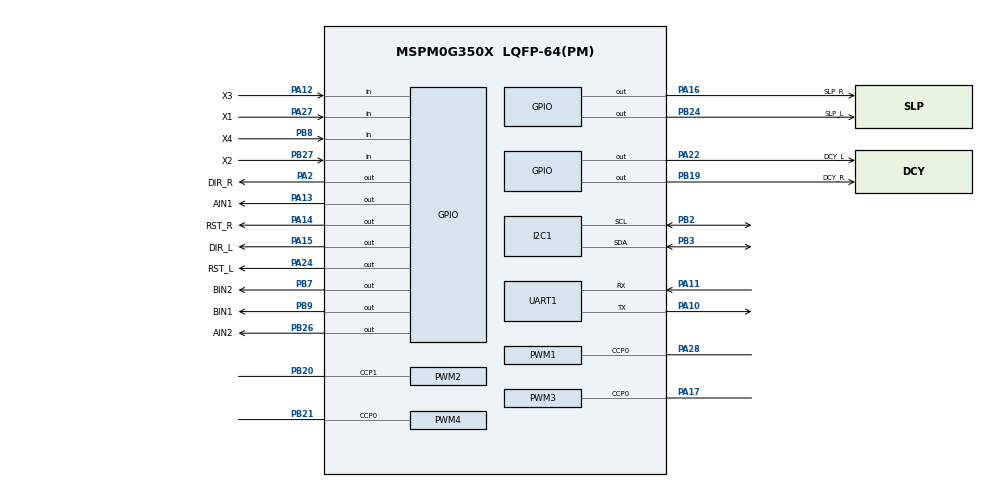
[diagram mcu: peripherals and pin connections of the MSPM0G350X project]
/**
 * @cliArgs --device "MSPM0G350X" --part "Default" --package "LQFP-64(PM)" --product "mspm0_sdk@2.10.00.04"
 * @versions {"tool":"1.26.2+4477"}
 */

/**
 * Import the modules used in this configuration.
 */
const GPIO    = scripting.addModule("/ti/driverlib/GPIO", {}, false);
const GPIO1   = GPIO.addInstance();
const GPIO2   = GPIO.addInstance();
const GPIO3   = GPIO.addInstance();
const GPIO4   = GPIO.addInstance();
const GPIO5   = GPIO.addInstance();
const I2C     = scripting.addModule("/ti/driverlib/I2C", {}, false);
const I2C1    = I2C.addInstance();
const I2C2    = I2C.addInstance();
const PWM     = scripting.addModule("/ti/driverlib/PWM", {}, false);
const PWM1    = PWM.addInstance();
const PWM2    = PWM.addInstance();
const PWM3    = PWM.addInstance();
const PWM4    = PWM.addInstance();
const SYSCTL  = scripting.addModule("/ti/driverlib/SYSCTL");
const SYSTICK = scripting.addModule("/ti/driverlib/SYSTICK");
const UART    = scripting.addModule("/ti/driverlib/UART", {}, false);
const UART1   = UART.addInstance();

/**
 * Write custom configuration values to the imported modules.
 */
const divider9       = system.clockTree["UDIV"];
divider9.divideValue = 2;

const multiplier2         = system.clockTree["PLL_QDIV"];
multiplier2.multiplyValue = 4;

const mux4       = system.clockTree["EXHFMUX"];
mux4.inputSelect = "EXHFMUX_XTAL";

const mux8       = system.clockTree["HSCLKMUX"];
mux8.inputSelect = "HSCLKMUX_SYSPLL0";

const mux12       = system.clockTree["SYSPLLMUX"];
mux12.inputSelect = "zSYSPLLMUX_HFCLK";

const pinFunction4       = system.clockTree["HFXT"];
pinFunction4.inputFreq   = 40;
pinFunction4.enable      = true;
pinFunction4.HFXTStartup = 10;

GPIO1.$name                         = "Motor_l";
GPIO1.associatedPins.create(2);
GPIO1.associatedPins[0].$name       = "AIN1";
GPIO1.associatedPins[0].pin.$assign = "PA13";
GPIO1.associatedPins[1].$name       = "AIN2";
GPIO1.associatedPins[1].pin.$assign = "PB26";

const Board = scripting.addModule("/ti/driverlib/Board", {}, false);

GPIO2.$name                         = "Motor_2";
GPIO2.associatedPins.create(2);
GPIO2.associatedPins[0].$name       = "BIN1";
GPIO2.associatedPins[0].pin.$assign = "PB9";
GPIO2.associatedPins[1].$name       = "BIN2";
GPIO2.associatedPins[1].pin.$assign = "PB7";

GPIO3.$name                         = "TRACE";
GPIO3.associatedPins.create(4);
GPIO3.associatedPins[0].$name       = "X1";
GPIO3.associatedPins[0].direction   = "INPUT";
GPIO3.associatedPins[0].pin.$assign = "PA27";
GPIO3.associatedPins[1].$name       = "X2";
GPIO3.associatedPins[1].direction   = "INPUT";
GPIO3.associatedPins[1].pin.$assign = "PB27";
GPIO3.associatedPins[2].$name       = "X3";
GPIO3.associatedPins[2].direction   = "INPUT";
GPIO3.associatedPins[2].pin.$assign = "PA12";
GPIO3.associatedPins[3].$name       = "X4";
GPIO3.associatedPins[3].direction   = "INPUT";
GPIO3.associatedPins[3].pin.$assign = "PB8";

GPIO4.$name                         = "GIMBAL_MOTOR_GPIO_L";
GPIO4.associatedPins.create(4);
GPIO4.associatedPins[0].$name       = "RST_L";
GPIO4.associatedPins[0].pin.$assign = "PA24";
GPIO4.associatedPins[1].$name       = "SLP_L";
GPIO4.associatedPins[1].pin.$assign = "PB24";
GPIO4.associatedPins[2].$name       = "DCY_L";
GPIO4.associatedPins[2].pin.$assign = "PA22";
GPIO4.associatedPins[3].$name       = "DIR_L";
GPIO4.associatedPins[3].pin.$assign = "PA15";

GPIO5.$name                         = "GIMBAL_MOTOR_GPIO_R";
GPIO5.associatedPins.create(4);
GPIO5.associatedPins[0].$name       = "RST_R";
GPIO5.associatedPins[0].pin.$assign = "PA14";
GPIO5.associatedPins[1].$name       = "SLP_R";
GPIO5.associatedPins[1].pin.$assign = "PA16";
GPIO5.associatedPins[2].$name       = "DCY_R";
GPIO5.associatedPins[2].pin.$assign = "PB19";
GPIO5.associatedPins[3].$name       = "DIR_R";
GPIO5.associatedPins[3].pin.$assign = "PA2";

I2C1.$name                             = "OLED";
I2C1.basicEnableController             = true;
I2C1.advDigitalGlitchFilter            = "CLOCKS_1";
I2C1.advControllerRXFIFOTRIG           = "BYTES_8";
I2C1.advControllerTXFIFOTRIG           = "BYTES_7";
I2C1.enableDMAEvent1                   = false;
I2C1.enableDMAEvent2                   = false;
I2C1.peripheral.$assign                = "I2C1";
I2C1.peripheral.sdaPin.$assign         = "PB3";
I2C1.peripheral.sclPin.$assign         = "PB2";
I2C1.sdaPinConfig.$name                = "ti_driverlib_gpio_GPIOPinGeneric0";
I2C1.sdaPinConfig.hideOutputInversion  = scripting.forceWrite(false);
I2C1.sdaPinConfig.onlyInternalResistor = scripting.forceWrite(false);
I2C1.sdaPinConfig.passedPeripheralType = scripting.forceWrite("Digital");
I2C1.sdaPinConfig.enableConfig         = true;
I2C1.sdaPinConfig.internalResistor     = "PULL_UP";
I2C1.sclPinConfig.$name                = "ti_driverlib_gpio_GPIOPinGeneric1";
I2C1.sclPinConfig.hideOutputInversion  = scripting.forceWrite(false);
I2C1.sclPinConfig.onlyInternalResistor = scripting.forceWrite(false);
I2C1.sclPinConfig.passedPeripheralType = scripting.forceWrite("Digital");
I2C1.sclPinConfig.enableConfig         = true;
I2C1.sclPinConfig.internalResistor     = "PULL_UP";

I2C2.$name                             = "MPU6050";
I2C2.basicEnableController             = true;
I2C2.sdaPinConfig.$name                = "ti_driverlib_gpio_GPIOPinGeneric10";
I2C2.sdaPinConfig.hideOutputInversion  = scripting.forceWrite(false);
I2C2.sdaPinConfig.onlyInternalResistor = scripting.forceWrite(false);
I2C2.sdaPinConfig.passedPeripheralType = scripting.forceWrite("Digital");
I2C2.sclPinConfig.$name                = "ti_driverlib_gpio_GPIOPinGeneric11";
I2C2.sclPinConfig.hideOutputInversion  = scripting.forceWrite(false);
I2C2.sclPinConfig.onlyInternalResistor = scripting.forceWrite(false);
I2C2.sclPinConfig.passedPeripheralType = scripting.forceWrite("Digital");

PWM1.$name                              = "PWMA";
PWM1.timerStartTimer                    = true;
PWM1.ccIndex                            = [0];
PWM1.clockPrescale                      = 2;
PWM1.timerCount                         = 4000;
PWM1.pwmMode                            = "EDGE_ALIGN_UP";
PWM1.PWM_CHANNEL_0.$name                = "ti_driverlib_pwm_PWMTimerCC0";
PWM1.ccp0PinConfig.direction            = scripting.forceWrite("OUTPUT");
PWM1.ccp0PinConfig.hideOutputInversion  = scripting.forceWrite(false);
PWM1.ccp0PinConfig.onlyInternalResistor = scripting.forceWrite(false);
PWM1.ccp0PinConfig.passedPeripheralType = scripting.forceWrite("Digital");
PWM1.ccp0PinConfig.$name                = "ti_driverlib_gpio_GPIOPinGeneric4";
PWM1.peripheral.$assign                 = "TIMG7";
PWM1.peripheral.ccp0Pin.$assign         = "PA28";

PWM2.$name                              = "PWMB";
PWM2.timerStartTimer                    = true;
PWM2.ccIndex                            = [1];
PWM2.clockPrescale                      = 2;
PWM2.timerCount                         = 4000;
PWM2.pwmMode                            = "EDGE_ALIGN_UP";
PWM2.ccp1PinConfig.direction            = scripting.forceWrite("OUTPUT");
PWM2.ccp1PinConfig.hideOutputInversion  = scripting.forceWrite(false);
PWM2.ccp1PinConfig.onlyInternalResistor = scripting.forceWrite(false);
PWM2.ccp1PinConfig.passedPeripheralType = scripting.forceWrite("Digital");
PWM2.ccp1PinConfig.$name                = "ti_driverlib_gpio_GPIOPinGeneric6";
PWM2.peripheral.$assign                 = "TIMA0";
PWM2.peripheral.ccp1Pin.$assign         = "PB20";
PWM2.PWM_CHANNEL_1.$name                = "ti_driverlib_pwm_PWMTimerCC1";

PWM3.$name                              = "GIMBAL_MOTOR_PWM_L";
PWM3.clockPrescale                      = 2;
PWM3.ccIndex                            = [0];
PWM3.pwmMode                            = "EDGE_ALIGN_UP";
PWM3.clockDivider                       = 8;
PWM3.timerCount                         = 10000;
PWM3.PWM_CHANNEL_0.$name                = "ti_driverlib_pwm_PWMTimerCC2";
PWM3.PWM_CHANNEL_1.$name                = "ti_driverlib_pwm_PWMTimerCC3";
PWM3.PWM_CHANNEL_0.ccValue              = 5000;
PWM3.PWM_CHANNEL_0.dutyCycle            = 50;
PWM3.ccp0PinConfig.direction            = scripting.forceWrite("OUTPUT");
PWM3.ccp0PinConfig.hideOutputInversion  = scripting.forceWrite(false);
PWM3.ccp0PinConfig.onlyInternalResistor = scripting.forceWrite(false);
PWM3.ccp0PinConfig.passedPeripheralType = scripting.forceWrite("Digital");
PWM3.ccp0PinConfig.$name                = "ti_driverlib_gpio_GPIOPinGeneric5";
PWM3.ccp1PinConfig.$name                = "ti_driverlib_gpio_GPIOPinGeneric7";
PWM3.ccp1PinConfig.direction            = scripting.forceWrite("OUTPUT");
PWM3.ccp1PinConfig.hideOutputInversion  = scripting.forceWrite(false);
PWM3.ccp1PinConfig.onlyInternalResistor = scripting.forceWrite(false);
PWM3.ccp1PinConfig.passedPeripheralType = scripting.forceWrite("Digital");
PWM3.ccp0PinConfig.$name                = "ti_driverlib_gpio_GPIOPinGeneric5";
PWM3.peripheral.$assign                 = "TIMA1";
PWM3.peripheral.ccp0Pin.$assign         = "PA17";

PWM4.$name                              = "GIMBAL_MOTOR_PWM_R";
PWM4.ccIndex                            = [0];
PWM4.pwmMode                            = "EDGE_ALIGN_UP";
PWM4.clockDivider                       = 8;
PWM4.timerCount                         = 10000;
PWM4.PWM_CHANNEL_0.$name                = "ti_driverlib_pwm_PWMTimerCC4";
PWM4.PWM_CHANNEL_0.ccValue              = 5000;
PWM4.PWM_CHANNEL_0.dutyCycle            = 50;
PWM4.ccp0PinConfig.$name                = "ti_driverlib_gpio_GPIOPinGeneric8";
PWM4.ccp0PinConfig.direction            = scripting.forceWrite("OUTPUT");
PWM4.ccp0PinConfig.hideOutputInversion  = scripting.forceWrite(false);
PWM4.ccp0PinConfig.onlyInternalResistor = scripting.forceWrite(false);
PWM4.ccp0PinConfig.passedPeripheralType = scripting.forceWrite("Digital");
PWM4.peripheral.$assign                 = "TIMG8";
PWM4.peripheral.ccp0Pin.$assign         = "PB21";

SYSCTL.forceDefaultClkConfig = true;
SYSCTL.clockTreeEn           = true;

SYSTICK.periodEnable    = true;
SYSTICK.period          = 80000;
SYSTICK.interruptEnable = true;
SYSTICK.systickEnable   = true;

UART1.$name                    = "UART_0";
UART1.targetBaudRate           = 115200;
UART1.enabledInterrupts        = ["RX"];
UART1.peripheral.rxPin.$assign = "PA11";
UART1.peripheral.txPin.$assign = "PA10";
UART1.txPinConfig.$name        = "ti_driverlib_gpio_GPIOPinGeneric2";
UART1.rxPinConfig.$name        = "ti_driverlib_gpio_GPIOPinGeneric3";

/**
 * Pinmux solution for unlocked pins/peripherals. This ensures that minor changes to the automatic solver in a future
 * version of the tool will not impact the pinmux you originally saw.  These lines can be completely deleted in order to
 * re-solve from scratch.
 */
pinFunction4.peripheral.$suggestSolution           = "SYSCTL";
pinFunction4.peripheral.hfxInPin.$suggestSolution  = "PA5";
pinFunction4.peripheral.hfxOutPin.$suggestSolution = "PA6";
Board.peripheral.$suggestSolution                  = "DEBUGSS";
Board.peripheral.swclkPin.$suggestSolution         = "PA20";
Board.peripheral.swdioPin.$suggestSolution         = "PA19";
I2C2.peripheral.$suggestSolution                   = "I2C0";
I2C2.peripheral.sdaPin.$suggestSolution            = "PA0";
I2C2.peripheral.sclPin.$suggestSolution            = "PA1";
PWM3.peripheral.ccp1Pin.$suggestSolution           = "PA16";
PWM4.peripheral.ccp1Pin.$suggestSolution           = "PB11";
UART1.peripheral.$suggestSolution                  = "UART0";
